# MPU_PRM register map
Vendor: Texas Instruments
Peripheral module from a debugger description file (folder omap36xx).
Registers are 32-bit, access per field, reset 0x0 unless marked. A register's access mark holds for its fields unless they carry their own. Offsets are as the file gives them; lines under a group give offsets from that group; [hi:lo] are bit positions; {n}, {i} and the like mark numbered series; 'fields as' and 'values as' point back to an identical list; <NAME> marks a mode.

## MPU_PRM
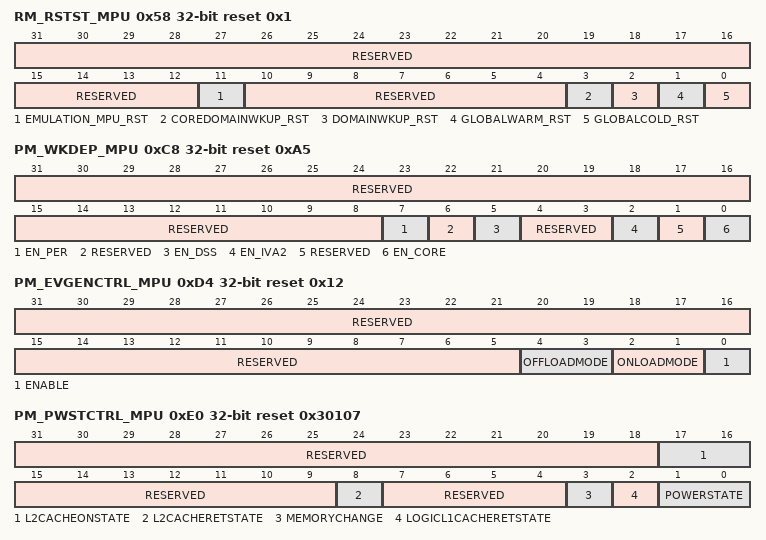
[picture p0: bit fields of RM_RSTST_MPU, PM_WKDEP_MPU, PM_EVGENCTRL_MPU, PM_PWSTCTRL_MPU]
0x58 RM_RSTST_MPU reset 0x1 — This register logs the different reset sources of the MPU domain. Each bit is set upon release of the domain reset signal. Must be cleared by software.
  [31:12] RESERVED ro — Write 0s for future compatibility. Read returns 0.
  [11] EMULATION_MPU_RST rw — Emulation reset
    0=EMULATION_MPU_RST_0_r (No emulation reset.); 0=EMULATION_MPU_RST_0_w (Status bit unchanged); 1=EMULATION_MPU_RST_1_r (MPU domain has been reset upon an emulation reset); 1=EMULATION_MPU_RST_1_w (Status bit is cleared to 0.)
  [10:4] RESERVED ro — Write 0s for future compatibility. Read returns 0.
  [3] COREDOMAINWKUP_RST rw — CORE domain wake-up reset
    0=COREDOMAINWKUP_RST_0_r (No power domain wake-up reset.); 0=COREDOMAINWKUP_RST_0_w (Status bit unchanged); 1=COREDOMAINWKUP_RST_1_r (MPU domain has been reset following a CORE power domain wake-up from OFF to ON.); 1=COREDOMAINWKUP_RST_1_w (Status bit is cleared to 0.)
  [2] DOMAINWKUP_RST rw — Power domain wake-up reset
    0=DOMAINWKUP_RST_0_r (No power domain wake-up reset.); 0=DOMAINWKUP_RST_0_w (Status bit unchanged); 1=DOMAINWKUP_RST_1_r (MPU domain has been reset following a MPU power domain wake-up.); 1=DOMAINWKUP_RST_1_w (Status bit is cleared to 0.)
  [1] GLOBALWARM_RST rw — Global warm reset
    0=GLOBALWARM_RST_0_r (No global warm reset.); 0=GLOBALWARM_RST_0_w (Status bit unchanged); 1=GLOBALWARM_RST_1_r (MPU domain has been reset upon a global warm reset); 1=GLOBALWARM_RST_1_w (Status bit is cleared to 0.)
  [0] GLOBALCOLD_RST rw — Global cold reset
    0=GLOBALCOLD_RST_0_r (No global cold reset.); 0=GLOBALCOLD_RST_0_w (Status bit unchanged); 1=GLOBALCOLD_RST_1_r (MPU domain has been reset upon a global cold reset); 1=GLOBALCOLD_RST_1_w (Status bit is cleared to 0.)
0xC8 PM_WKDEP_MPU reset 0xA5 — This register allows enabling or disabling the wake-up of the MPU domain upon another domain wakeup events.
  [31:8] RESERVED ro — Write 0s for future compatibility. Read returns 0.
  [7] EN_PER rw — PER domain dependency
    0=MPU domain is independent of PER domain wake-up event; 1=MPU domain is woken-up upon PER domain wake-up event
  [6] RESERVED ro — Write 0s for future compatibility. Read returns 0.
  [5] EN_DSS rw — DSS domain dependency
    0=MPU domain is independent of DSS domain wake-up event; 1=MPU domain is woken-up upon DSS domain wake-up event
  [4:3] RESERVED ro — Write 0s for future compatibility. Read returns 0.
  [2] EN_IVA2 rw — IVA2 domain dependency
    0=MPU domain is independent of IVA2 domain wake-up event; 1=MPU domain is woken-up upon IVA2 domain wake-up event
  [1] RESERVED ro — Write 0s for future compatibility. Read returns 0.
  [0] EN_CORE rw — CORE domain dependency
    0=MPU domain is independent of CORE domain wake-up event; 1=MPU domain is is woken-up upon CORE domain wake-up event
0xD4 PM_EVGENCTRL_MPU reset 0x12 — This register allows controlling the feature of the event generator.
  [31:5] RESERVED ro — Write 0s for future compatibility . Read returns 0
  [4:3] OFFLOADMODE rw — OFF load mode setting
    0=Load on update of; 2=Load on MPU standby signal assertion; 3=Auto load
  [2:1] ONLOADMODE rw — ON load mode setting
    0=Load on update of; 1=Load on MPU standby signal de-assertion; 3=Auto load
  [0] ENABLE rw — Event generator control
    0=Disable event generator; 1=Enable event generator
0xD8 PM_EVGENONTIM_MPU rw — This register sets the ON count duration of the event generator (number of system clock cycles).
  [31:0] ONTIMEVAL — Number of system clock cycles for the ON period.
0xDC PM_EVGENOFFTIM_MPU rw — This register sets the OFF count duration of the event generator (number of system clock cycles).
  [31:0] OFFTIMEVAL — Number of system clock cycles for the OFF period.
0xE0 PM_PWSTCTRL_MPU reset 0x30107 — This register controls the MPU domain power state transition.
  [31:18] RESERVED ro — Write 0s for future compatibility. Read returns 0.
  [17:16] L2CACHEONSTATE rw — L2 Cache memory state when domain is ON; Other enums: Reserved
    0=L2 Cache memory is OFF when domain is ON; 3=L2 Cache memory is ON when domain is ON
  [15:9] RESERVED ro — Write 0s for future compatibility. Read returns 0.
  [8] L2CACHERETSTATE rw — L2 Cache memory state when domain is RETENTION
    0=L2 Cache memory is OFF when domain is in RETENTION state; 1=L2 Cache memory is retained when domain is in RETENTION state
  [7:4] RESERVED ro — Write 0s for future compatibility. Read returns 0.
  [3] MEMORYCHANGE rw — Memory change control in ON state
    0=Disable memory change; 1=Enable memory change state in ON state. This bit is automaticaly cleared when memory state is effectively changed.
  [2] LOGICL1CACHERETSTATE rw — Logic and L1 Cache state when domain is RETENTION
    0=Logic and L1 Cache are OFF when domain is in RETENTION state; 1=Logic and L1 Cache are retained when domain is in RETENTION state
  [1:0] POWERSTATE rw — Power state control
    0=OFF state; 1=RETENTION state; 3=ON state
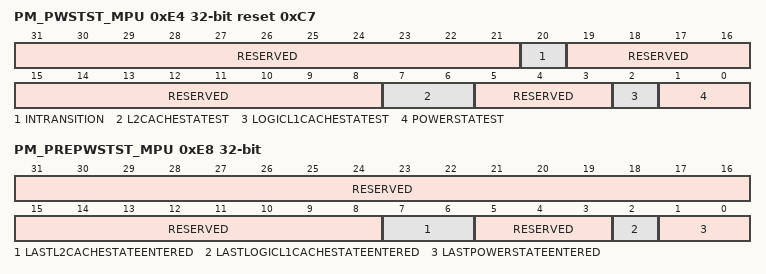
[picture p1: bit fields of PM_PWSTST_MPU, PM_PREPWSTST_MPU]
0xE4 PM_PWSTST_MPU ro reset 0xC7 — This register provides a status on the MPU domain power state.
  [31:21] RESERVED — Read returns 0.
  [20] INTRANSITION — Domain transition status
    0=No transition; 1=MPU power domain transition is in progress
  [19:8] RESERVED — Read returns 0.
  [7:6] L2CACHESTATEST — L2 Cache memory state status
    0=L2 Cache memory is OFF; 1=L2 Cache memory is in RETENTION; 3=L2 Cache memory is ON
  [5:3] RESERVED — Read returns 0.
  [2] LOGICL1CACHESTATEST — Logic and L1 Cache state status
    0=MPU domain logic and L1 Cache is OFF; 1=MPU domain logic and L1 Cache is ON
  [1:0] POWERSTATEST — Current power state status
    0=Power domain is OFF; 1=Power domain is in RETENTION; 2=Power domain is INACTIVE; 3=Power domain is ON
0xE8 PM_PREPWSTST_MPU — This register provides a status on the MPU domain previous power state. It indicates the state entered during the last sleep transition.
  [31:8] RESERVED ro — Read returns 0.
  [7:6] LASTL2CACHESTATEENTERED rw — Last L2 Cache memory state entered
    0=L2 Cache memory was previously OFF; 1=L2 Cache memory was previously in RETENTION; 3=L2 Cache memory was previously ON
  [5:3] RESERVED ro — Read returns 0.
  [2] LASTLOGICL1CACHESTATEENTERED rw — Last logic and L1 Cache state entered
    0=MPU domain logic and L1 Cache was previously OFF; 1=MPU domain logic and L1 Cache was previously ON
  [1:0] LASTPOWERSTATEENTERED rw
    0=MPU domain was previously OFF; 1=MPU domain was previously in RETENTION; 2=MPU domain was previously INACTIVE; 3=MPU domain was previously ON
